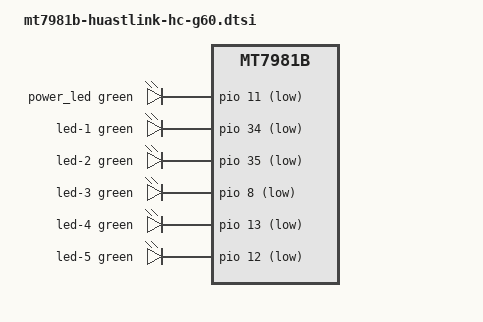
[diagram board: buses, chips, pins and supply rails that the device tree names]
// SPDX-License-Identifier: GPL-2.0-or-later OR MIT
/*
 * Huastlink HC-G60: HC-G80 platform (MT7981B, MT7531, 512 MiB, M.2 5G slot)
 * with 4 LAN on the MT7531 (no RTL8370), other LED GPIOs and 256 MiB
 * SPI-NAND. GPIOs as in the vendor HC-G60 V01 GPIO table.
 */

#include "mt7981b-huastlink-hc-g80.dtsi"

/ {
	gpio-export {
		/* GPIO6 high = SIM1, low = SIM2; default to SIM1 */
		sim {
			gpios = <&pio 6 GPIO_ACTIVE_HIGH>;
			gpio-export,output = <1>;
		};
	};

	/delete-node/ gpio-leds;

	gpio-leds {
		compatible = "gpio-leds";

		power_led: led-0 {
			function = LED_FUNCTION_STATUS;
			color = <LED_COLOR_ID_GREEN>;
			gpios = <&pio 11 GPIO_ACTIVE_LOW>;
		};

		led-1 {
			function = LED_FUNCTION_WLAN;
			function-enumerator = <1>;
			color = <LED_COLOR_ID_GREEN>;
			gpios = <&pio 34 GPIO_ACTIVE_LOW>;
			linux,default-trigger = "phy0tpt";
		};

		led-2 {
			function = LED_FUNCTION_WLAN;
			function-enumerator = <2>;
			color = <LED_COLOR_ID_GREEN>;
			gpios = <&pio 35 GPIO_ACTIVE_LOW>;
			linux,default-trigger = "phy1tpt";
		};

		led-3 {
			function = LED_FUNCTION_WAN;
			color = <LED_COLOR_ID_GREEN>;
			gpios = <&pio 8 GPIO_ACTIVE_LOW>;
		};

		led-4 {
			function = LED_FUNCTION_LAN;
			color = <LED_COLOR_ID_GREEN>;
			gpios = <&pio 13 GPIO_ACTIVE_LOW>;
		};

		led-5 {
			function = LED_FUNCTION_MOBILE;
			color = <LED_COLOR_ID_GREEN>;
			gpios = <&pio 12 GPIO_ACTIVE_LOW>;
		};
	};
};
